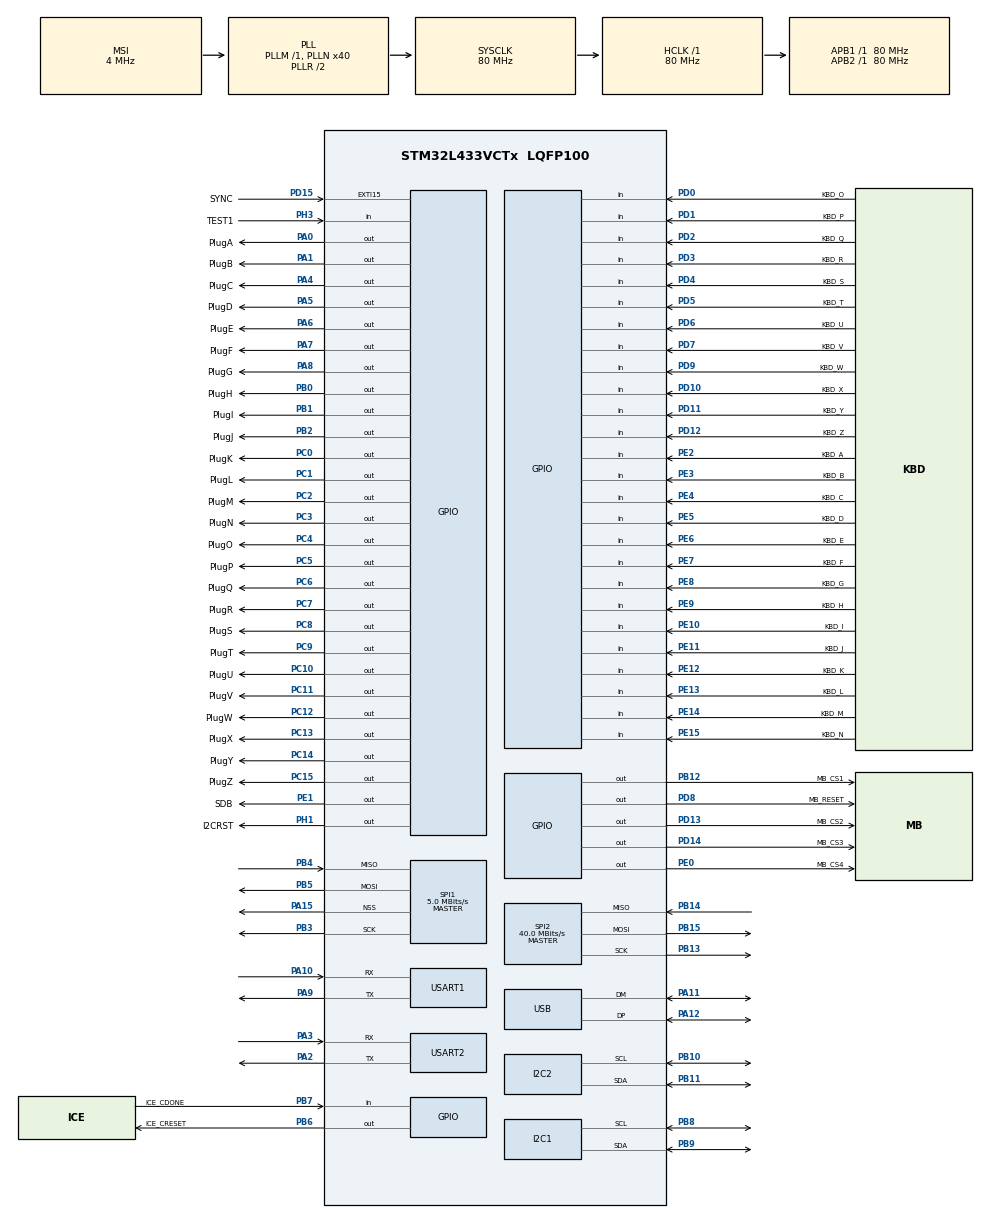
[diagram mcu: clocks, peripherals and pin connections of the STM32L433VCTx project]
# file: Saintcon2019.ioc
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Dma.Request0=SPI1_TX
Dma.SPI1_TX.0.Direction=DMA_MEMORY_TO_PERIPH
Dma.SPI1_TX.0.Instance=DMA1_Channel3
Dma.SPI1_TX.0.MemDataAlignment=DMA_MDATAALIGN_BYTE
Dma.SPI1_TX.0.MemInc=DMA_MINC_ENABLE
Dma.SPI1_TX.0.Mode=DMA_NORMAL
Dma.SPI1_TX.0.PeriphDataAlignment=DMA_PDATAALIGN_BYTE
Dma.SPI1_TX.0.PeriphInc=DMA_PINC_DISABLE
Dma.SPI1_TX.0.Priority=DMA_PRIORITY_LOW
Mcu.Family=STM32L4
Mcu.Name=STM32L433VCTx
Mcu.Package=LQFP100
NVIC.DMA1_Channel3_IRQn=true\:0\:0\:false\:false\:true\:false\:true
NVIC.EXTI15_10_IRQn=true\:0\:0\:false\:false\:true\:true\:true
NVIC.I2C1_ER_IRQn=true\:0\:0\:false\:false\:true\:true\:true
NVIC.I2C1_EV_IRQn=true\:0\:0\:false\:false\:true\:true\:true
NVIC.I2C2_ER_IRQn=true\:0\:0\:false\:false\:true\:true\:true
NVIC.I2C2_EV_IRQn=true\:0\:0\:false\:false\:true\:true\:true
NVIC.PriorityGroup=NVIC_PRIORITYGROUP_4
NVIC.SPI1_IRQn=true\:0\:0\:false\:false\:true\:true\:true
NVIC.SPI2_IRQn=true\:0\:0\:false\:false\:true\:true\:true
NVIC.TIM1_UP_TIM16_IRQn=true\:0\:0\:false\:false\:true\:true\:true
NVIC.USART1_IRQn=true\:0\:0\:false\:false\:true\:true\:true
NVIC.USART2_IRQn=true\:0\:0\:false\:false\:true\:true\:true
NVIC.USB_IRQn=true\:0\:0\:false\:false\:true\:true\:true
PA0.GPIO_Label=PlugA
PA0.GPIO_ModeDefaultOutputPP=GPIO_MODE_OUTPUT_OD
PA0.GPIO_PuPd=GPIO_PULLUP
PA0.PinState=GPIO_PIN_SET
PA0.Signal=GPIO_Output
PA1.GPIO_Label=PlugB
PA1.GPIO_ModeDefaultOutputPP=GPIO_MODE_OUTPUT_OD
PA1.GPIO_PuPd=GPIO_PULLUP
PA1.PinState=GPIO_PIN_SET
PA1.Signal=GPIO_Output
PA10.Mode=Asynchronous
PA10.Signal=USART1_RX
PA11.Mode=Device
PA11.Signal=USB_DM
PA12.Mode=Device
PA12.Signal=USB_DP
PA13\ (JTMS-SWDIO).Mode=Serial_Wire
PA13\ (JTMS-SWDIO).Signal=SYS_JTMS-SWDIO
PA14\ (JTCK-SWCLK).Mode=Serial_Wire
PA14\ (JTCK-SWCLK).Signal=SYS_JTCK-SWCLK
PA15\ (JTDI).Mode=NSS_Signal_Hard_Output
PA15\ (JTDI).Signal=SPI1_NSS
PA2.Mode=Asynchronous
PA2.Signal=USART2_TX
PA3.Mode=Asynchronous
PA3.Signal=USART2_RX
PA4.GPIO_Label=PlugC
PA4.GPIO_ModeDefaultOutputPP=GPIO_MODE_OUTPUT_OD
PA4.GPIO_PuPd=GPIO_PULLUP
PA4.PinState=GPIO_PIN_SET
PA4.Signal=GPIO_Output
PA5.GPIO_Label=PlugD
PA5.GPIO_ModeDefaultOutputPP=GPIO_MODE_OUTPUT_OD
PA5.GPIO_PuPd=GPIO_PULLUP
PA5.PinState=GPIO_PIN_SET
PA5.Signal=GPIO_Output
PA6.GPIO_Label=PlugE
PA6.GPIO_ModeDefaultOutputPP=GPIO_MODE_OUTPUT_OD
PA6.GPIO_PuPd=GPIO_PULLUP
PA6.PinState=GPIO_PIN_SET
PA6.Signal=GPIO_Output
PA7.GPIO_Label=PlugF
PA7.GPIO_ModeDefaultOutputPP=GPIO_MODE_OUTPUT_OD
PA7.GPIO_PuPd=GPIO_PULLUP
PA7.GPIO_Speed=GPIO_SPEED_FREQ_LOW
PA7.PinState=GPIO_PIN_SET
PA7.Signal=GPIO_Output
PA8.GPIO_Label=PlugG
PA8.GPIO_ModeDefaultOutputPP=GPIO_MODE_OUTPUT_OD
PA8.GPIO_PuPd=GPIO_PULLUP
PA8.GPIO_Speed=GPIO_SPEED_FREQ_LOW
PA8.PinState=GPIO_PIN_SET
PA8.Signal=GPIO_Output
PA9.Mode=Asynchronous
PA9.Signal=USART1_TX
PB0.GPIO_Label=PlugH
PB0.GPIO_ModeDefaultOutputPP=GPIO_MODE_OUTPUT_OD
PB0.GPIO_PuPd=GPIO_PULLUP
PB0.GPIO_Speed=GPIO_SPEED_FREQ_LOW
PB0.PinState=GPIO_PIN_SET
PB0.Signal=GPIO_Output
PB1.GPIO_Label=PlugI
PB1.GPIO_ModeDefaultOutputPP=GPIO_MODE_OUTPUT_OD
PB1.GPIO_PuPd=GPIO_PULLUP
PB1.GPIO_Speed=GPIO_SPEED_FREQ_LOW
PB1.PinState=GPIO_PIN_SET
PB1.Signal=GPIO_Output
PB10.Mode=I2C
PB10.Signal=I2C2_SCL
PB11.Mode=I2C
PB11.Signal=I2C2_SDA
PB12.GPIO_Label=MB_CS1
PB12.Signal=GPIO_Output
PB13.Mode=Full_Duplex_Master
PB13.Signal=SPI2_SCK
PB14.Mode=Full_Duplex_Master
PB14.Signal=SPI2_MISO
PB15.Mode=Full_Duplex_Master
PB15.Signal=SPI2_MOSI
PB2.GPIO_Label=PlugJ
PB2.GPIO_ModeDefaultOutputPP=GPIO_MODE_OUTPUT_OD
PB2.GPIO_PuPd=GPIO_PULLUP
PB2.GPIO_Speed=GPIO_SPEED_FREQ_LOW
PB2.PinState=GPIO_PIN_SET
PB2.Signal=GPIO_Output
PB3\ (JTDO-TRACESWO).Mode=Full_Duplex_Master
PB3\ (JTDO-TRACESWO).Signal=SPI1_SCK
PB4\ (NJTRST).Mode=Full_Duplex_Master
PB4\ (NJTRST).Signal=SPI1_MISO
PB5.Mode=Full_Duplex_Master
PB5.Signal=SPI1_MOSI
PB6.GPIO_Label=ICE_CRESET
PB6.Signal=GPIO_Output
PB7.GPIO_Label=ICE_CDONE
PB7.Signal=GPIO_Input
PB8.Mode=I2C
PB8.Signal=I2C1_SCL
PB9.Mode=I2C
PB9.Signal=I2C1_SDA
PC0.GPIO_Label=PlugK
PC0.GPIO_ModeDefaultOutputPP=GPIO_MODE_OUTPUT_OD
PC0.GPIO_PuPd=GPIO_PULLUP
PC0.GPIO_Speed=GPIO_SPEED_FREQ_LOW
PC0.PinState=GPIO_PIN_SET
PC0.Signal=GPIO_Output
PC1.GPIO_Label=PlugL
PC1.GPIO_ModeDefaultOutputPP=GPIO_MODE_OUTPUT_OD
PC1.GPIO_PuPd=GPIO_PULLUP
PC1.GPIO_Speed=GPIO_SPEED_FREQ_LOW
PC1.PinState=GPIO_PIN_SET
PC1.Signal=GPIO_Output
PC10.GPIO_Label=PlugU
PC10.GPIO_ModeDefaultOutputPP=GPIO_MODE_OUTPUT_OD
PC10.GPIO_PuPd=GPIO_PULLUP
PC10.GPIO_Speed=GPIO_SPEED_FREQ_LOW
PC10.PinState=GPIO_PIN_SET
PC10.Signal=GPIO_Output
PC11.GPIO_Label=PlugV
PC11.GPIO_ModeDefaultOutputPP=GPIO_MODE_OUTPUT_OD
PC11.GPIO_PuPd=GPIO_PULLUP
PC11.GPIO_Speed=GPIO_SPEED_FREQ_LOW
PC11.PinState=GPIO_PIN_SET
PC11.Signal=GPIO_Output
PC12.GPIO_Label=PlugW
PC12.GPIO_ModeDefaultOutputPP=GPIO_MODE_OUTPUT_OD
PC12.GPIO_PuPd=GPIO_PULLUP
PC12.GPIO_Speed=GPIO_SPEED_FREQ_LOW
PC12.PinState=GPIO_PIN_SET
PC12.Signal=GPIO_Output
PC13.GPIO_Label=PlugX
PC13.GPIO_ModeDefaultOutputPP=GPIO_MODE_OUTPUT_OD
PC13.GPIO_PuPd=GPIO_PULLUP
PC13.GPIO_Speed=GPIO_SPEED_FREQ_LOW
PC13.PinState=GPIO_PIN_SET
PC13.Signal=GPIO_Output
PC14-OSC32_IN\ (PC14).GPIO_Label=PlugY
PC14-OSC32_IN\ (PC14).GPIO_ModeDefaultOutputPP=GPIO_MODE_OUTPUT_OD
PC14-OSC32_IN\ (PC14).GPIO_PuPd=GPIO_PULLUP
PC14-OSC32_IN\ (PC14).GPIO_Speed=GPIO_SPEED_FREQ_LOW
PC14-OSC32_IN\ (PC14).PinState=GPIO_PIN_SET
PC14-OSC32_IN\ (PC14).Signal=GPIO_Output
PC15-OSC32_OUT\ (PC15).GPIO_Label=PlugZ
PC15-OSC32_OUT\ (PC15).GPIO_ModeDefaultOutputPP=GPIO_MODE_OUTPUT_OD
PC15-OSC32_OUT\ (PC15).GPIO_PuPd=GPIO_PULLUP
PC15-OSC32_OUT\ (PC15).GPIO_Speed=GPIO_SPEED_FREQ_LOW
PC15-OSC32_OUT\ (PC15).PinState=GPIO_PIN_SET
PC15-OSC32_OUT\ (PC15).Signal=GPIO_Output
PC2.GPIO_Label=PlugM
PC2.GPIO_ModeDefaultOutputPP=GPIO_MODE_OUTPUT_OD
PC2.GPIO_PuPd=GPIO_PULLUP
PC2.GPIO_Speed=GPIO_SPEED_FREQ_LOW
PC2.PinState=GPIO_PIN_SET
PC2.Signal=GPIO_Output
PC3.GPIO_Label=PlugN
PC3.GPIO_ModeDefaultOutputPP=GPIO_MODE_OUTPUT_OD
PC3.GPIO_PuPd=GPIO_PULLUP
PC3.GPIO_Speed=GPIO_SPEED_FREQ_LOW
PC3.PinState=GPIO_PIN_SET
PC3.Signal=GPIO_Output
PC4.GPIO_Label=PlugO
PC4.GPIO_ModeDefaultOutputPP=GPIO_MODE_OUTPUT_OD
PC4.GPIO_PuPd=GPIO_PULLUP
PC4.GPIO_Speed=GPIO_SPEED_FREQ_LOW
PC4.PinState=GPIO_PIN_SET
PC4.Signal=GPIO_Output
PC5.GPIO_Label=PlugP
PC5.GPIO_ModeDefaultOutputPP=GPIO_MODE_OUTPUT_OD
PC5.GPIO_PuPd=GPIO_PULLUP
PC5.GPIO_Speed=GPIO_SPEED_FREQ_LOW
PC5.PinState=GPIO_PIN_SET
PC5.Signal=GPIO_Output
PC6.GPIO_Label=PlugQ
PC6.GPIO_ModeDefaultOutputPP=GPIO_MODE_OUTPUT_OD
PC6.GPIO_PuPd=GPIO_PULLUP
PC6.GPIO_Speed=GPIO_SPEED_FREQ_LOW
PC6.PinState=GPIO_PIN_SET
PC6.Signal=GPIO_Output
PC7.GPIO_Label=PlugR
PC7.GPIO_ModeDefaultOutputPP=GPIO_MODE_OUTPUT_OD
PC7.GPIO_PuPd=GPIO_PULLUP
PC7.GPIO_Speed=GPIO_SPEED_FREQ_LOW
PC7.PinState=GPIO_PIN_SET
PC7.Signal=GPIO_Output
PC8.GPIO_Label=PlugS
PC8.GPIO_ModeDefaultOutputPP=GPIO_MODE_OUTPUT_OD
PC8.GPIO_PuPd=GPIO_PULLUP
PC8.GPIO_Speed=GPIO_SPEED_FREQ_LOW
PC8.PinState=GPIO_PIN_SET
PC8.Signal=GPIO_Output
PC9.GPIO_Label=PlugT
PC9.GPIO_ModeDefaultOutputPP=GPIO_MODE_OUTPUT_OD
PC9.GPIO_PuPd=GPIO_PULLUP
PC9.GPIO_Speed=GPIO_SPEED_FREQ_LOW
PC9.PinState=GPIO_PIN_SET
PC9.Signal=GPIO_Output
PD0.GPIO_Label=KBD_O
PD0.GPIO_PuPd=GPIO_PULLUP
PD0.Signal=GPIO_Input
PD1.GPIO_Label=KBD_P
PD1.GPIO_PuPd=GPIO_PULLUP
PD1.Signal=GPIO_Input
PD10.GPIO_Label=KBD_X
PD10.GPIO_PuPd=GPIO_PULLUP
PD10.Signal=GPIO_Input
PD11.GPIO_Label=KBD_Y
PD11.GPIO_PuPd=GPIO_PULLUP
PD11.Signal=GPIO_Input
PD12.GPIO_Label=KBD_Z
PD12.GPIO_PuPd=GPIO_PULLUP
PD12.Signal=GPIO_Input
PD13.GPIO_Label=MB_CS2
PD13.Signal=GPIO_Output
PD14.GPIO_Label=MB_CS3
PD14.Signal=GPIO_Output
PD15.GPIO_Label=SYNC
PD15.GPIO_ModeDefaultEXTI=GPIO_MODE_IT_FALLING
PD15.GPIO_PuPd=GPIO_PULLUP
PD15.Signal=GPXTI15
PD2.GPIO_Label=KBD_Q
PD2.GPIO_PuPd=GPIO_PULLUP
PD2.Signal=GPIO_Input
PD3.GPIO_Label=KBD_R
PD3.GPIO_PuPd=GPIO_PULLUP
PD3.Signal=GPIO_Input
PD4.GPIO_Label=KBD_S
PD4.GPIO_PuPd=GPIO_PULLUP
PD4.Signal=GPIO_Input
PD5.GPIO_Label=KBD_T
PD5.GPIO_PuPd=GPIO_PULLUP
PD5.Signal=GPIO_Input
PD6.GPIO_Label=KBD_U
PD6.GPIO_PuPd=GPIO_PULLUP
PD6.Signal=GPIO_Input
PD7.GPIO_Label=KBD_V
PD7.GPIO_PuPd=GPIO_PULLUP
PD7.Signal=GPIO_Input
PD8.GPIO_Label=MB_RESET
PD8.Signal=GPIO_Output
PD9.GPIO_Label=KBD_W
PD9.GPIO_PuPd=GPIO_PULLUP
PD9.Signal=GPIO_Input
PE0.GPIO_Label=MB_CS4
PE0.Signal=GPIO_Output
PE1.GPIO_Label=SDB
PE1.Signal=GPIO_Output
PE10.GPIO_Label=KBD_I
PE10.GPIO_PuPd=GPIO_PULLUP
PE10.Signal=GPIO_Input
PE11.GPIO_Label=KBD_J
PE11.GPIO_PuPd=GPIO_PULLUP
PE11.Signal=GPIO_Input
PE12.GPIO_Label=KBD_K
PE12.GPIO_PuPd=GPIO_PULLUP
PE12.Signal=GPIO_Input
PE13.GPIO_Label=KBD_L
PE13.GPIO_PuPd=GPIO_PULLUP
PE13.Signal=GPIO_Input
PE14.GPIO_Label=KBD_M
PE14.GPIO_PuPd=GPIO_PULLUP
PE14.Signal=GPIO_Input
PE15.GPIO_Label=KBD_N
PE15.GPIO_PuPd=GPIO_PULLUP
PE15.Signal=GPIO_Input
PE2.GPIO_Label=KBD_A
PE2.GPIO_PuPd=GPIO_PULLUP
PE2.Signal=GPIO_Input
PE3.GPIO_Label=KBD_B
PE3.GPIO_PuPd=GPIO_PULLUP
PE3.Signal=GPIO_Input
PE4.GPIO_Label=KBD_C
PE4.GPIO_PuPd=GPIO_PULLUP
PE4.Signal=GPIO_Input
PE5.GPIO_Label=KBD_D
PE5.GPIO_PuPd=GPIO_PULLUP
PE5.Signal=GPIO_Input
PE6.GPIO_Label=KBD_E
PE6.GPIO_PuPd=GPIO_PULLUP
PE6.Signal=GPIO_Input
PE7.GPIO_Label=KBD_F
PE7.GPIO_PuPd=GPIO_PULLUP
PE7.Signal=GPIO_Input
PE8.GPIO_Label=KBD_G
PE8.GPIO_PuPd=GPIO_PULLUP
PE8.Signal=GPIO_Input
PE9.GPIO_Label=KBD_H
PE9.GPIO_PuPd=GPIO_PULLUP
PE9.Signal=GPIO_Input
PH0-OSC_IN\ (PH0).Mode=HSE-External-Clock-Source
PH0-OSC_IN\ (PH0).Signal=RCC_OSC_IN
PH1-OSC_OUT\ (PH1).GPIO_Label=I2CRST
PH1-OSC_OUT\ (PH1).Signal=GPIO_Output
PH3-BOOT0.GPIO_Label=TEST1
PH3-BOOT0.Signal=GPIO_Input
ProjectManager.HeapSize=0x200
ProjectManager.StackSize=0x400
ProjectManager.TargetToolchain=STM32CubeIDE
RCC.ADCFreq_Value=48000000
RCC.AHBFreq_Value=80000000
RCC.APB1Freq_Value=80000000
RCC.APB1TimFreq_Value=80000000
RCC.APB2Freq_Value=80000000
RCC.APB2TimFreq_Value=80000000
RCC.CortexFreq_Value=80000000
RCC.HCLKFreq_Value=80000000
RCC.HSE_VALUE=12000000
RCC.HSI48_VALUE=48000000
RCC.HSI_VALUE=16000000
RCC.LSE_VALUE=32768
RCC.MSI_VALUE=4000000
RCC.PLLN=40
RCC.PLLSAI1N=24
RCC.SYSCLKFreq_VALUE=80000000
RCC.SYSCLKSource=RCC_SYSCLKSOURCE_PLLCLK
RCC.USBFreq_Value=48000000
RCC.VCOOutputFreq_Value=160000000
SPI1.BaudRatePrescaler=SPI_BAUDRATEPRESCALER_16
SPI1.CRCCalculation=SPI_CRCCALCULATION_DISABLE
SPI1.CalculateBaudRate=5.0 MBits/s
SPI1.DataSize=SPI_DATASIZE_8BIT
SPI1.Direction=SPI_DIRECTION_2LINES
SPI1.Mode=SPI_MODE_MASTER
SPI1.NSSPMode=SPI_NSS_PULSE_ENABLE
SPI1.VirtualNSS=VM_NSSHARD
SPI1.VirtualType=VM_MASTER
SPI2.CalculateBaudRate=40.0 MBits/s
SPI2.Direction=SPI_DIRECTION_2LINES
SPI2.Mode=SPI_MODE_MASTER
SPI2.VirtualType=VM_MASTER
TIM16.Period=2666
TIM16.Prescaler=999
USART1.VirtualMode-Asynchronous=VM_ASYNC
USART2.VirtualMode-Asynchronous=VM_ASYNC
USB_DEVICE.CLASS_NAME_FS=CDC
USB_DEVICE.VirtualMode=Cdc
USB_DEVICE.VirtualModeFS=Cdc_FS
VP_TIM16_VS_ClockSourceINT.Mode=Enable_Timer
VP_USB_DEVICE_VS_USB_DEVICE_CDC_FS.Mode=CDC_FS
board=custom

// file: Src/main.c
/* USER CODE BEGIN Header */
/**
  ******************************************************************************
  * @file           : main.c
  * @brief          : Main program body
  ******************************************************************************
  * @attention
  *
  * <h2><center>&copy; Copyright (c) 2019 STMicroelectronics.
  * All rights reserved.</center></h2>
  *
  * This software component is licensed by ST under BSD 3-Clause license,
  * the "License"; You may not use this file except in compliance with the
  * License. You may obtain a copy of the License at:
  *                        opensource.org/licenses/BSD-3-Clause
  *
  ******************************************************************************
  */
/* USER CODE END Header */

#include "main.h"
#include "dma.h"
#include "i2c.h"
#include "spi.h"
#include "tim.h"
#include "usart.h"
#include "usb_device.h"
#include "gpio.h"

/* USER CODE BEGIN Includes */
#include "stdint.h"
#include "drv_is31fl.h"
#include "usbd_cdc_if.h"
#include "stm32l4xx_hal.h"
#include "errno.h"
#include "stm32l433xx.h"
#include "matrix.h"
#include "lampboard.h"
#include "keyboard.h"
#include "images.h"
#include "custommessage.h"
#include "eeprom_emul.h"
#include "stdlib.h"
#include "testmode.h"
#include "animations.h"
#include "menu.h"
#include "plugboard.h"
/* USER CODE END Includes */

/* USER CODE BEGIN PD */
#define LED_I2C_MASTER_NUM &hi2c1

/* USER CODE END PD */

/* USER CODE BEGIN PV */

//Uncomment to enable badge test mode
//#define BADGE_TEST_CODE

const char ERROR_COMMANDER[] = "You must have a commander to receive your debriefing. Invite one to join your ring.";
const uint8_t ERROR_COMMANDER_LENGTH = 83;
const char INITIAL_RING[] = "Helga has been captured! Your mission is to decode messages to enable Allied forces to save her from the Enemy. Intercepted messages can be picked up at Hut 6. Good luck!";
const uint8_t INITIAL_RING_LENGTH = 170;

const char RING1_MESSAGE[] = "Well done Agents! Helga has been rescued, but Trevor was recaptured. Your new mission is to stop the Enemy from extracting the vital intelligence that Trevor holds. Good luck!";
const char RING2_MESSAGE[] = "Trevor tragically paid the ultimate price, but hopefully the Enemy didn’t learn of our newest defense. Your new mission is to determine what the Enemy knows about Project Firewall.";
const char RING3_MESSAGE[] = "Mission Complete! Thanks to your decoding skills Helga was saved! Sadly Trevor gave his life to protect Project Firewall, but his sacrifice will never be forgotten #TrevorForget. Thanks for playing!";
const uint8_t RING1_MESSAGE_LENGTH = 175;
const uint8_t RING2_MESSAGE_LENGTH = 180;
const uint8_t RING3_MESSAGE_LENGTH = 198;

/* Virtual address Tab defined by the user: 0x0000 and 0xFFFF values are prohibited */
uint16_t VirtAddVarTab[NB_OF_VARIABLES];
uint32_t Index = 0;
__IO uint32_t ErasingOnGoing = 0;
uint32_t VarDataTab[NB_OF_VARIABLES] = {0};
uint32_t VarValue = 0;

uint8_t badgeLevel = 1; //Change to start on level 1 after the conference, when it's not possible to link up badges
uint8_t badgeNum = 1;

volatile uint8_t rbyte;

volatile uint8_t nextFrame = 0;

volatile int syncCounter = 0;

volatile int LeftRecvBufferHead = 0;
volatile int LeftRecvBufferTail = 0;
volatile uint8_t LeftRecvBuffer[UART_BUFFER_SIZE + 1];
volatile int RightRecvBufferHead = 0;
volatile int RightRecvBufferTail = 0;
volatile uint8_t RightRecvBuffer[UART_BUFFER_SIZE + 1];

/* USER CODE END PV */

void SystemClock_Config(void);

/* USER CODE BEGIN 0 */
/*
 * Delay for n msec
 */
static void
msec_delay(int n)
{
	HAL_Delay(n);
}
/* USER CODE END 0 */

int main(void)
{
  /* USER CODE BEGIN 1 */
	EE_Status ee_status = EE_OK;
  /* USER CODE END 1 */

  /* MCU Configuration--------------------------------------------------------*/

  /* Reset of all peripherals, Initializes the Flash interface and the Systick. */
  HAL_Init();

  /* Configure the system clock */
  SystemClock_Config();

  /* Initialize all configured peripherals */
  MX_GPIO_Init();
  MX_DMA_Init();
  MX_I2C1_Init();
  MX_I2C2_Init();
  MX_SPI1_Init();
  MX_SPI2_Init();
  MX_USART1_UART_Init();
  MX_USART2_UART_Init();
  MX_USB_DEVICE_Init();
  MX_TIM16_Init();
  /* USER CODE BEGIN 2 */

  /* Enable and set FLASH Interrupt priority */
    /* FLASH interrupt is used for the purpose of pages clean up under interrupt */
    HAL_NVIC_SetPriority(FLASH_IRQn, 0, 0);
    HAL_NVIC_EnableIRQ(FLASH_IRQn);

    /* Unlock the Flash Program Erase controller */
    HAL_FLASH_Unlock();
    /* Enable Power Control clock */
      __HAL_RCC_PWR_CLK_ENABLE();

      /* Set user List of Virtual Address variables: 0x0000 and 0xFFFF values are prohibited */
        for (VarValue = 0; VarValue < NB_OF_VARIABLES; VarValue++)
        {
          VirtAddVarTab[VarValue] = (uint16_t)(10*VarValue + 1);
        }

      /* Set EEPROM emulation firmware to erase all potentially incompletely erased
           pages if the system came from an asynchronous reset. Conditional erase is
           safe to use if all Flash operations where completed before the system reset */
        if(__HAL_PWR_GET_FLAG(PWR_FLAG_SB) == RESET)
        {

          /* System reset comes from a power-on reset: Forced Erase */
          /* Initialize EEPROM emulation driver (mandatory) */
          ee_status = EE_Init(VirtAddVarTab, EE_FORCED_ERASE);
          if(ee_status != EE_OK) {Error_Handler();}
        }
        else
        {
          /* Clear the Standby flag */
          __HAL_PWR_CLEAR_FLAG(PWR_FLAG_SB);

          /* System reset comes from a STANDBY wakeup: Conditional Erase*/
          /* Initialize EEPROM emulation driver (mandatory) */
          ee_status = EE_Init(VirtAddVarTab, EE_CONDITIONAL_ERASE);
          if(ee_status != EE_OK) {Error_Handler();}
        }

  HAL_TIM_Base_Start_IT(&htim16);

  FPGA_Init();

  HAL_GPIO_WritePin(GPIOE, GPIO_PIN_1,GPIO_PIN_SET);

  drv_is31fl_init();

  //uint8_t buffer[10];

  drv_is31fl_set_page(1);
  //HAL_I2C_Master_Transmit(&hi2c1, 0x50<<1, buffer,1,100);
  //drv_is31fl_send_value(10,128);

  //uint8_t x = 0;
  //uint8_t leddelay = 100;
  /* USER CODE END 2 */

  /* Infinite loop */
  /* USER CODE BEGIN WHILE */
//matrix_fillRect(0,0,64,16,COLOR_WHITE);
//matrix_update();
  //while(1);
  //uint8_t address = 70;

  InitMinibadges();

  /*
  HAL_I2C_Master_Transmit(&hi2c2, address, data, 2, 100);

  data[0] = 0x01;
  for(int x=0; x<2; x++){
	  data[1] = 0x01;
	  HAL_I2C_Master_Transmit(&hi2c2, address, data, 2, 100);
	  msec_delay(100);
	  data[1] = 0x02;
	  HAL_I2C_Master_Transmit(&hi2c2, address, data, 2, 100);
	  msec_delay(100);
	  data[1] = 0x04;
	  HAL_I2C_Master_Transmit(&hi2c2, address, data, 2, 100);
	  msec_delay(100);
	  data[1] = 0x08;
	  HAL_I2C_Master_Transmit(&hi2c2, address, data, 2, 100);
	  msec_delay(100);
	  data[1] = 0x10;
	  HAL_I2C_Master_Transmit(&hi2c2, address, data, 2, 100);
	  msec_delay(100);
	  data[1] = 0x20;
	  HAL_I2C_Master_Transmit(&hi2c2, address, data, 2, 100);
	  msec_delay(100);
	  data[1] = 0x40;
	  HAL_I2C_Master_Transmit(&hi2c2, address, data, 2, 100);
	  msec_delay(100);
	  data[1] = 0x80;
	  HAL_I2C_Master_Transmit(&hi2c2, address, data, 2, 100);
	  msec_delay(100);
  }
  data[1] = 0xFF;
  HAL_I2C_Master_Transmit(&hi2c2, address, data, 2, 100);
*/

  //Character Test
  //matrix_drawChar("SAINTCON",0,0,COLOR_RED);
 // matrix_update();
  //msec_delay(500);

  //Drawing Test
  /*matrix_drawRect(0,0,64,16,COLOR_RED);
  matrix_drawRect(1,1,62,14,COLOR_GREEN);
  matrix_drawRect(2,2,60,12,COLOR_BLUE);
  matrix_drawRect(3,3,58,10,COLOR_WHITE);
  matrix_drawRect(4,4,56,8,COLOR_RED);
  matrix_drawRect(5,5,54,6,COLOR_GREEN);
  matrix_drawRect(6,6,52,4,COLOR_BLUE);
  matrix_drawRect(7,7,50,2,COLOR_WHITE);
  matrix_update();
  msec_delay(500);
   */

  uint8_t data;
  if(EE_ReadVariable8bits(VirtAddVarTab[EEP_MESSAGE_CODE_1], &data) != EE_OK){
	  TestMode();
  }

  EE_ReadVariable8bits(VirtAddVarTab[EEP_CHALLENGE_LEVEL], &badgeLevel);
  if(badgeLevel == 0) badgeLevel = 1; //Fix for after conference - Skip initial ring and start on level 1

  //Image Test
  //matrix_drawImage(sc,0,0,38,16);
  matrix_drawImage(sc4,0,0,64,16);
  matrix_update();
  msec_delay(1000);

  menu();

/*
  for(int x=64; x>0; x-=2){
	  matrix_clear();
	  matrix_drawImageScaled(sc4,(64-x)/2,0,64,16,x,16);
	  matrix_update();
	  msec_delay(500);
  }
*/
  /*
  for(int i=0; i<16; i++){
	  matrix_clear();
	  matrix_drawLine(0,0,63,i, COLOR_RED);
	  matrix_update();
	  msec_delay(200);
  }
  for(int i=63; i>0; i--){
  	  matrix_clear();
  	  matrix_drawLine(0,0,i,15, COLOR_RED);
  	  matrix_update();
  	  msec_delay(200);
    }*/
  /*for(int i=0; i<16; i++){
  	  matrix_clear();
  	  matrix_drawLine(0,0,63,i, COLOR_RED);
  	  matrix_update();
  	  msec_delay(500);
    }
  for(int i=0; i<16; i++){
  	  matrix_clear();
  	  matrix_drawLine(0,0,63,i, COLOR_RED);
  	  matrix_update();
  	  msec_delay(500);
    }*/

  while (1){

	  if(nextFrame == 1){ //Set by Timer16 - 30FPS
		  nextFrame = 0;
		  //Button Test Code
		  uint32_t buttons = 0;
		  buttons = keyboardUpdate();
		  for(int x=0; x<26; x++){
			  if((buttons>>x) & 1){
				  lampboard_setLamp(x, COLOR_RED);
				  HAL_UART_Transmit(&huart1, (unsigned char*)"A", 1, 500);
			  } else {
				  lampboard_setLamp(x, COLOR_GREEN);
			  }
		  }
		  if((buttons>>31)&1){//LongPress
			  for(int x=0; x<26; x++){
				  lampboard_setLamp(x, COLOR_BLUE);
			  }
		  }
		  lampboard_update();
		  //msec_delay(50);
	  }

  }
    /* USER CODE END WHILE */

}

void SystemClock_Config(void)
{
  RCC_OscInitTypeDef RCC_OscInitStruct = {0};
  RCC_ClkInitTypeDef RCC_ClkInitStruct = {0};
  RCC_PeriphCLKInitTypeDef PeriphClkInit = {0};

  /** Initializes the CPU, AHB and APB busses clocks
  */
  RCC_OscInitStruct.OscillatorType = RCC_OSCILLATORTYPE_MSI;
  RCC_OscInitStruct.MSIState = RCC_MSI_ON;
  RCC_OscInitStruct.MSICalibrationValue = 0;
  RCC_OscInitStruct.MSIClockRange = RCC_MSIRANGE_6;
  RCC_OscInitStruct.PLL.PLLState = RCC_PLL_ON;
  RCC_OscInitStruct.PLL.PLLSource = RCC_PLLSOURCE_MSI;
  RCC_OscInitStruct.PLL.PLLM = 1;
  RCC_OscInitStruct.PLL.PLLN = 40;
  RCC_OscInitStruct.PLL.PLLP = RCC_PLLP_DIV7;
  RCC_OscInitStruct.PLL.PLLQ = RCC_PLLQ_DIV2;
  RCC_OscInitStruct.PLL.PLLR = RCC_PLLR_DIV2;
  if (HAL_RCC_OscConfig(&RCC_OscInitStruct) != HAL_OK)
  {
    Error_Handler();
  }
  /** Initializes the CPU, AHB and APB busses clocks
  */
  RCC_ClkInitStruct.ClockType = RCC_CLOCKTYPE_HCLK|RCC_CLOCKTYPE_SYSCLK
                              |RCC_CLOCKTYPE_PCLK1|RCC_CLOCKTYPE_PCLK2;
  RCC_ClkInitStruct.SYSCLKSource = RCC_SYSCLKSOURCE_PLLCLK;
  RCC_ClkInitStruct.AHBCLKDivider = RCC_SYSCLK_DIV1;
  RCC_ClkInitStruct.APB1CLKDivider = RCC_HCLK_DIV1;
  RCC_ClkInitStruct.APB2CLKDivider = RCC_HCLK_DIV1;

  if (HAL_RCC_ClockConfig(&RCC_ClkInitStruct, FLASH_LATENCY_4) != HAL_OK)
  {
    Error_Handler();
  }
  PeriphClkInit.PeriphClockSelection = RCC_PERIPHCLK_USART1|RCC_PERIPHCLK_USART2
                              |RCC_PERIPHCLK_I2C1|RCC_PERIPHCLK_I2C2
                              |RCC_PERIPHCLK_USB;
  PeriphClkInit.Usart1ClockSelection = RCC_USART1CLKSOURCE_PCLK2;
  PeriphClkInit.Usart2ClockSelection = RCC_USART2CLKSOURCE_PCLK1;
  PeriphClkInit.I2c1ClockSelection = RCC_I2C1CLKSOURCE_PCLK1;
  PeriphClkInit.I2c2ClockSelection = RCC_I2C2CLKSOURCE_PCLK1;
  PeriphClkInit.UsbClockSelection = RCC_USBCLKSOURCE_PLLSAI1;
  PeriphClkInit.PLLSAI1.PLLSAI1Source = RCC_PLLSOURCE_MSI;
  PeriphClkInit.PLLSAI1.PLLSAI1M = 1;
  PeriphClkInit.PLLSAI1.PLLSAI1N = 24;
  PeriphClkInit.PLLSAI1.PLLSAI1P = RCC_PLLP_DIV7;
  PeriphClkInit.PLLSAI1.PLLSAI1Q = RCC_PLLQ_DIV2;
  PeriphClkInit.PLLSAI1.PLLSAI1R = RCC_PLLR_DIV2;
  PeriphClkInit.PLLSAI1.PLLSAI1ClockOut = RCC_PLLSAI1_48M2CLK;
  if (HAL_RCCEx_PeriphCLKConfig(&PeriphClkInit) != HAL_OK)
  {
    Error_Handler();
  }
  /** Configure the main internal regulator output voltage
  */
  if (HAL_PWREx_ControlVoltageScaling(PWR_REGULATOR_VOLTAGE_SCALE1) != HAL_OK)
  {
    Error_Handler();
  }
}

/* USER CODE BEGIN 4 */
void HAL_GPIO_EXTI_Callback(uint16_t GPIO_Pin){
	//Called when an external interrupt pin is triggered
	if(GPIO_Pin == SYNC_Pin){
		//syncCounter ++;
	}
	//if(GPIO_Pin == GPIO_PIN_2){
		//dispDelay = 500;
		//for(int x=0; x<100; x++){
		//HAL_UART_Transmit(&huart1, (unsigned char*)"A", 1, 500);
		//msec_delay(10);
		//}
	//}
}

void HAL_TIM_PeriodElapsedCallback(TIM_HandleTypeDef *htim){
	if(htim == &htim16){ //Timer16 - 30fps timer
		//Set flag here to alert main loop to draw new frame
		nextFrame = 1;
	}
	/*static uint8_t state = 0;
	if(state == 0){
		state = 1;
		drv_is31fl_send_value(0,0);
	} else {
		state = 0;
		drv_is31fl_send_value(0,128);
	}*/
}

void UART_Right_IRQ(UART_HandleTypeDef *huart){ //huart1
	uint32_t isrflags   = READ_REG(huart->Instance->ISR);
	  uint32_t cr1its     = READ_REG(huart->Instance->CR1);
	  uint32_t cr3its     = READ_REG(huart->Instance->CR3);

	  uint32_t errorflags;
	  //uint32_t errorcode;

	  if (((isrflags & USART_ISR_RXNE) != 0U) //Receive Mode
			  && ((cr1its & USART_CR1_RXNEIE) != 0U)){
		  /* If no error occurs */
		  errorflags = (isrflags & (uint32_t)(USART_ISR_PE | USART_ISR_FE | USART_ISR_ORE | USART_ISR_NE));
		  if (errorflags == 0U)
		  {
			  if(RightRecvBufferHead == ((RightRecvBufferTail - 1 + UART_BUFFER_SIZE) % UART_BUFFER_SIZE)){
				  //Buffer Full

				  rbyte = (uint8_t)huart->Instance->RDR;
			  } else {
				  RightRecvBuffer[RightRecvBufferHead] = (uint8_t)huart->Instance->RDR;
				  RightRecvBufferHead = (RightRecvBufferHead + 1) % UART_BUFFER_SIZE;
			  }
		  }
	  } else {
		  rbyte = (uint8_t)huart->Instance->RDR;
	  }

	  __HAL_UART_CLEAR_FLAG(huart, UART_CLEAR_PEF);
	  __HAL_UART_CLEAR_FLAG(huart, UART_CLEAR_FEF);
	  __HAL_UART_CLEAR_FLAG(huart, UART_CLEAR_NEF);
	  __HAL_UART_CLEAR_FLAG(huart, UART_CLEAR_OREF);
	  __HAL_UART_CLEAR_FLAG(huart, UART_CLEAR_WUF);
}

void UART_Left_IRQ(UART_HandleTypeDef *huart){ //huart2
	uint32_t isrflags   = READ_REG(huart->Instance->ISR);
		  uint32_t cr1its     = READ_REG(huart->Instance->CR1);
		  uint32_t cr3its     = READ_REG(huart->Instance->CR3);

		  uint32_t errorflags;
		  uint32_t errorcode;

		  if ((isrflags & USART_ISR_RXNE) != 0U){ //Receive Mode
				  //&& ((cr1its & USART_CR1_RXNEIE) != 0U)){
			  /* If no error occurs */
			  errorflags = (isrflags & (uint32_t)(USART_ISR_PE | USART_ISR_FE | USART_ISR_ORE | USART_ISR_NE));
			  if (errorflags == 0U)
			  {
				  if(LeftRecvBufferHead == ((LeftRecvBufferTail - 1 + UART_BUFFER_SIZE) % UART_BUFFER_SIZE)){
					  //Buffer Full
					  rbyte = (uint8_t)huart->Instance->RDR;
				  } else {
					  LeftRecvBuffer[LeftRecvBufferHead] = (uint8_t)huart->Instance->RDR;
					  LeftRecvBufferHead = (LeftRecvBufferHead + 1) % UART_BUFFER_SIZE;
				  }
			  }
		  } else {
			  rbyte = (uint8_t)huart->Instance->RDR;
		  }

		  __HAL_UART_CLEAR_FLAG(huart, UART_CLEAR_PEF);
		  __HAL_UART_CLEAR_FLAG(huart, UART_CLEAR_FEF);
		  __HAL_UART_CLEAR_FLAG(huart, UART_CLEAR_NEF);
		  __HAL_UART_CLEAR_FLAG(huart, UART_CLEAR_OREF);
		  __HAL_UART_CLEAR_FLAG(huart, UART_CLEAR_WUF);

}

void CheckSerial(){

	uint8_t leftBadgeLevel = 0;
	uint8_t leftBadgeNum = 0;
	//uint8_t leftBadgeNum = 25; //for testing
	//Left Serial
	if(LeftRecvBufferHead == LeftRecvBufferTail){
		//Buffer Empty
	} else {
		uint8_t data = LeftRecvBuffer[LeftRecvBufferTail];
		//LeftRecvBufferTail = (LeftRecvBufferTail + 1) % UART_BUFFER_SIZE;
		if(data == SYNC){
			DisplayAnimation();
		} else {
			LeftRecvBufferTail = (LeftRecvBufferTail + 1) % UART_BUFFER_SIZE;
		}

	}

	uint8_t rightBadgeLevel = 0;
	//Right Serial
	if(RightRecvBufferHead == RightRecvBufferTail){
		//Buffer Empty
	} else {
		uint8_t data = RightRecvBuffer[RightRecvBufferTail];

		if(data == badgeNum){
			DisplayAnimation();
		} else {
			RightRecvBufferTail = (RightRecvBufferTail + 1) % UART_BUFFER_SIZE;
		}

		if(data == SYNC + 1){ //201
			uint8_t out[8];
			uint8_t data = 0;
			out[0] = SYNC;
			out[1] = badgeLevel;
			if(badgeLevel < 1){
				for(int x=0; x<6; x++){
					out[x + 2] = 'A';
				}
			} else if(badgeLevel < 2){
				for(int x=0; x<6; x++){
					EE_ReadVariable8bits(EEP_MESSAGE_CODE_1 + x, &data);
					out[x + 2] = data+65;
				}
			} else if(badgeLevel < 3){
				for(int x=0; x<6; x++){
					EE_ReadVariable8bits(EEP_MESSAGE_CODE_2 + x, &data);
					out[x + 2] = data+65;
				}
			} else if(badgeLevel < 4){
				for(int x=0; x<6; x++){
					EE_ReadVariable8bits(EEP_MESSAGE_CODE_3 + x, &data);
					out[x + 2] = data+65;
				}
			} else if(badgeLevel < 5){
				for(int x=0; x<6; x++){
					out[x + 2]='A';
				}
			} else if(badgeLevel < 6){
				for(int x=0; x<6; x++){
					EE_ReadVariable8bits(EEP_MESSAGE_CODE_4 + x, &data);
					out[x + 2] = data+65;
				}
			} else if(badgeLevel < 7){
				for(int x=0; x<6; x++){
					EE_ReadVariable8bits(EEP_MESSAGE_CODE_5 + x, &data);
					out[x + 2] = data+65;
				}
			} else if(badgeLevel < 8){
				for(int x=0; x<6; x++){
					EE_ReadVariable8bits(EEP_MESSAGE_CODE_6 + x, &data);
					out[x + 2] = data+65;
				}
			} else if(badgeLevel < 9){
				for(int x=0; x<6; x++){
					out[x + 2]='A';
				}
			} else if(badgeLevel < 10){
				for(int x=0; x<6; x++){
					EE_ReadVariable8bits(EEP_MESSAGE_CODE_7 + x, &data);
					out[x + 2] = data+65;
				}
			} else if(badgeLevel < 11){
				for(int x=0; x<6; x++){
					EE_ReadVariable8bits(EEP_MESSAGE_CODE_8 + x, &data);
					out[x + 2] = data+65;
				}
			} else if(badgeLevel < 12){
				for(int x=0; x<6; x++){
					EE_ReadVariable8bits(EEP_MESSAGE_CODE_9 + x, &data);
					out[x + 2] = data+65;
				}
			} else if(badgeLevel < 13){
				for(int x=0; x<6; x++){
					out[x + 2] = 'A';
				}
			} else if(badgeLevel < 14){
				for(int x=0; x<6; x++){
					out[x + 2] = 'Z';
				}
			}
			HAL_UART_Transmit(&huart1, out, 8, 100); //Send Code to Printer
			//matrix_clear();
			//matrix_drawCharCentered("PRINTING", 0, 4, COLOR_GREEN);
			//matrix_update();
			//HAL_Delay(1000);
		}
				/*if(data == SYNC){
					while(RightRecvBufferHead == RightRecvBufferTail);
					rightBadgeLevel = RightRecvBuffer[RightRecvBufferTail];
					RightRecvBufferTail = (RightRecvBufferTail + 1) % UART_BUFFER_SIZE;
					while(RightRecvBufferHead == RightRecvBufferTail);
					uint8_t rightBadgeNum = RightRecvBuffer[RightRecvBufferTail];
					RightRecvBufferTail = (RightRecvBufferTail + 1) % UART_BUFFER_SIZE;
					while(RightRecvBufferHead == RightRecvBufferTail);
					uint8_t rightBadgeCommand = RightRecvBuffer[RightRecvBufferTail];
					RightRecvBufferTail = (RightRecvBufferTail + 1) % UART_BUFFER_SIZE;

					uint8_t ack[5];
					switch(rightBadgeCommand){
					case 2: //Ack
						ack[0] = SYNC;
						ack[1] = badgeLevel;
						//ack[2] = leftBadgeNum + 1;
						ack[2] = 26;
						ack[3] = 4;
						ack[4] = 0;
						HAL_UART_Transmit(&huart1, ack, 5, 100); //Send Display Rotor Animation
						DisplayAnimation(leftBadgeLevel, leftBadgeNum, 4, badgeLevel);
						break;

					case 5: //Request Level Code
						;
						uint8_t code[10] = {SYNC, badgeLevel, 1, 6};
						if(badgeLevel == 1){
							for(int x=4; x<10; x++){
								EE_ReadVariable8bits(EEP_MESSAGE_CODE_1 + x, code[x]);
							}
						}
						if(badgeLevel == 2){
							for(int x=4; x<10; x++){
								EE_ReadVariable8bits(EEP_MESSAGE_CODE_2 + x, code[x]);
							}
						}
						if(badgeLevel == 3){
							for(int x=4; x<10; x++){
								EE_ReadVariable8bits(EEP_MESSAGE_CODE_3 + x, code[x]);
							}
						}
						if(badgeLevel == 4){
							for(int x=4; x<10; x++){
								EE_ReadVariable8bits(EEP_MESSAGE_CODE_4 + x, code[x]);
							}
						}
						if(badgeLevel == 5){
							for(int x=4; x<10; x++){
								EE_ReadVariable8bits(EEP_MESSAGE_CODE_5 + x, code[x]);
							}
						}
						if(badgeLevel == 6){
							for(int x=4; x<10; x++){
								EE_ReadVariable8bits(EEP_MESSAGE_CODE_6 + x, code[x]);
							}
						}
						if(badgeLevel == 7){
							for(int x=4; x<10; x++){
								EE_ReadVariable8bits(EEP_MESSAGE_CODE_7 + x, code[x]);
							}
						}
						if(badgeLevel == 8){
							for(int x=4; x<10; x++){
								EE_ReadVariable8bits(EEP_MESSAGE_CODE_8 + x, code[x]);
							}
						}
						if(badgeLevel == 9){
							for(int x=4; x<10; x++){
								EE_ReadVariable8bits(EEP_MESSAGE_CODE_9 + x, code[x]);
							}
						}
						HAL_UART_Transmit(&huart1, code, 10, 100); //Send Level Code
						break;
					}
				}*/
	}

	//uint8_t outData[4] = {SYNC, badgeLevel, leftBadgeNum + 1, 1};
	//uint8_t outData[4] = {SYNC, badgeLevel, 26, 1};
	//HAL_UART_Transmit(&huart1, outData, 4, 100); //Send Hello to Right side
	uint8_t outData[5] = {SYNC, badgeLevel, 1, 4, 0};
	HAL_UART_Transmit(&huart1, outData, 5, 100); //Send Rotor Command to Right
}

/* USER CODE END 4 */

void Error_Handler(void)
{
}

/************************ (C) COPYRIGHT STMicroelectronics *****END OF FILE****/
